VERSION ""

NS_ :

BS_:

BU_: XXX

BO_ 312 MSG_138: 8 XXX
 SG_ SIG_00 : 48|4@1- (1,0) [-1.0|-1.0] "" XXX
 SG_ SIG_01 : 56|4@1- (1,0) [7.0|7.0] "" XXX

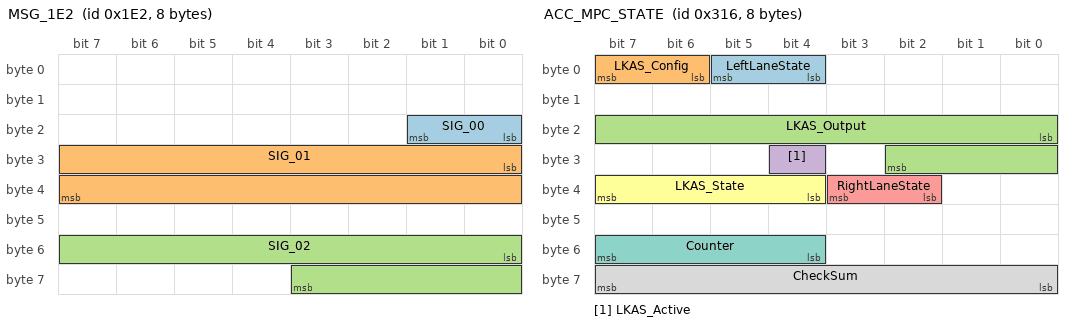
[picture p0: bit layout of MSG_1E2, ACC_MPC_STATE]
BO_ 482 MSG_1E2: 8 XXX
 SG_ SIG_00 : 16|2@1+ (1,0) [2.0|2.0] "" XXX
 SG_ SIG_01 : 24|16@1+ (0.12207217517357137,0) [0.0|8000.0] "" XXX
 SG_ SIG_02 : 48|12@1- (0.06227106227106227,-40) [-166.5970695970696|87.46886446886447] "" XXX

BO_ 790 ACC_MPC_STATE: 8 XXX

 SG_ LeftLaneState : 4|2@1+ (1,0) [0|3] "" XXX
 SG_ LKAS_Config : 6|2@1+ (1,0) [0|3] "" XXX
 SG_ LKAS_Output : 16|11@1- (1,0) [-1024|1023] "" XXX
 SG_ LKAS_Active : 28|1@1+ (1,0) [0|3] "" XXX
 SG_ RightLaneState : 34|2@1+ (1,0) [0|3] "" XXX
 SG_ LKAS_State : 36|4@1+ (1,0) [0|3] "" XXX
 SG_ Counter : 52|4@1+ (1,0) [0|15] "" XXX
 SG_ CheckSum : 56|8@1+ (1,0) [0|15] "" XXX

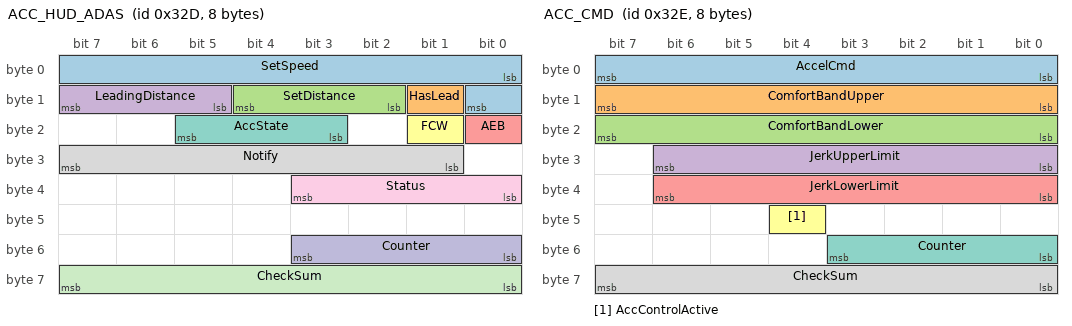
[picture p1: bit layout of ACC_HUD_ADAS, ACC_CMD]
BO_ 813 ACC_HUD_ADAS: 8 XXX

 SG_ SetSpeed : 0|9@1+ (0.5,0) [0|255.5] "" XXX
 SG_ HasLead : 9|1@1+ (1,0) [0|1] "" XXX
 SG_ SetDistance : 10|3@1+ (1,0) [0|7] "" XXX
 SG_ LeadingDistance : 13|3@1+ (1,0) [0|7] "" XXX
 SG_ AEB : 16|1@1+ (1,0) [0|1] "" XXX
 SG_ FCW : 17|1@1+ (1,0) [0|1] "" XXX
 SG_ AccState : 19|3@1+ (1,0) [0|1] "" XXX
 SG_ Notify : 25|7@1+ (1,0) [0|127] "" XXX
 SG_ Status : 32|4@1+ (1,0) [0|15] "" XXX
 SG_ Counter : 48|4@1+ (1,0) [0|15] "" XXX
 SG_ CheckSum : 56|8@1+ (1,0) [0|255] "" XXX

BO_ 814 ACC_CMD: 8 XXX

 SG_ AccelCmd : 0|8@1+ (0.05,-5) [-5|7.75] "" XXX
 SG_ ComfortBandUpper : 8|8@1+ (0.05,-5) [0|1.26] "" XXX
 SG_ ComfortBandLower : 16|8@1+ (0.05,-5) [0|1.26] "" XXX
 SG_ JerkUpperLimit : 24|7@1+ (0.2,0) [0|12.7] "" XXX
 SG_ JerkLowerLimit : 32|7@1+ (0.2,-16) [0|12.7] "" XXX
 SG_ AccControlActive : 44|1@0+ (1,0) [0|1] "" XXX
 SG_ Counter : 48|4@1+ (1,0) [0|15] "" XXX
 SG_ CheckSum : 56|8@1+ (1,0) [0|255] "" XXX

BO_ 815 ACC_AEB: 8 XXX

 SG_ Counter : 48|4@1+ (1,0) [0|15] "" XXX
 SG_ CheckSum : 56|8@1+ (1,0) [0|255] "" XXX

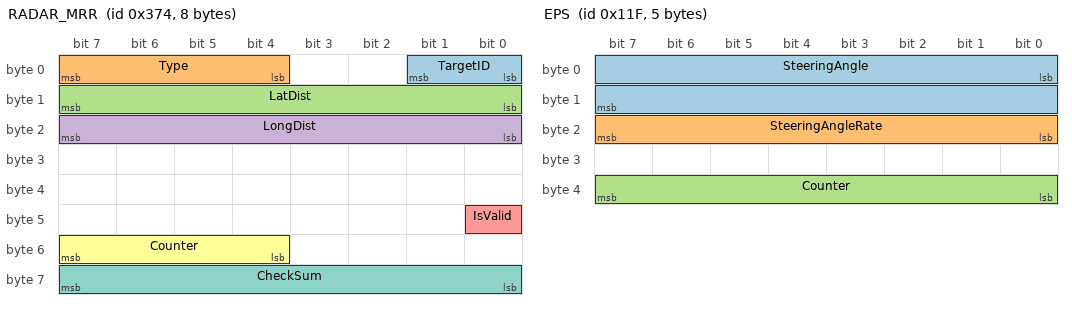
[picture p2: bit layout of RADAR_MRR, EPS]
BO_ 884 RADAR_MRR: 8 XXX

 SG_ TargetID : 1|2@0+ (1,0) [0|3] "" XXX
 SG_ Type : 7|4@0+ (1,0) [0|15] "" XXX
 SG_ LatDist : 15|8@0+ (0.1,-12) [0|255] "" XXX
 SG_ LongDist : 23|8@0+ (1,-100) [0|255] "" XXX
 SG_ IsValid : 40|1@0+ (1,0) [0|3] "" XXX
 SG_ Counter : 52|4@1+ (1,0) [0|15] "" XXX
 SG_ CheckSum : 56|8@1+ (1,0) [0|255] "" XXX

BO_ 287 EPS: 5 XXX

 SG_ SteeringAngle : 0|16@1- (0.1,0) [-450|450] "" XXX
 SG_ SteeringAngleRate : 16|8@1+ (4,0) [0|1020] "" XXX
 SG_ Counter : 32|8@1+ (1,0) [0|255] "" XXX

BO_ 296 MSG_128: 8 XXX
 SG_ SIG_00 : 48|4@1- (1,0) [2.0|2.0] "" XXX
 SG_ SIG_01 : 56|4@1- (1,0) [-4.0|-4.0] "" XXX

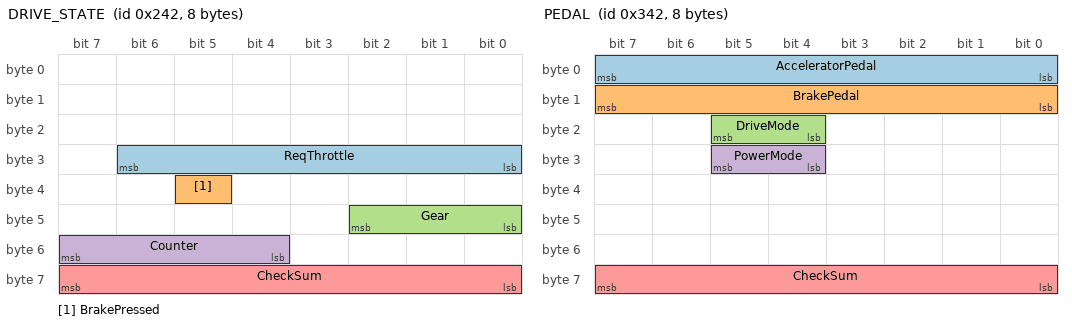
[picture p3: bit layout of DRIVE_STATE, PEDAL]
BO_ 578 DRIVE_STATE: 8 XXX

 SG_ ReqThrottle : 30|7@0+ (1,0) [0|127] "" XXX
 SG_ BrakePressed : 37|1@0+ (1,0) [0|1] "" XXX
 SG_ Gear : 40|3@1+ (1,0) [0|7] "" XXX
 SG_ Counter : 52|4@1+ (1,0) [0|15] "" XXX
 SG_ CheckSum : 56|8@1+ (1,0) [0|255] "" XXX

BO_ 300 MSG_12C: 8 XXX
 SG_ SIG_00 : 48|4@1- (1,0) [0.0|0.0] "" XXX
 SG_ SIG_01 : 56|4@1- (1,0) [-6.0|-6.0] "" XXX

BO_ 834 PEDAL: 8 XXX

 SG_ AcceleratorPedal : 0|8@1+ (1,0) [0|255] "" XXX
 SG_ BrakePedal : 8|8@1+ (1,0) [0|255] "" XXX
 SG_ DriveMode : 20|2@1+ (1,0) [0|255] "" XXX
 SG_ PowerMode : 28|2@1+ (1,0) [0|1] "" XXX
 SG_ CheckSum : 56|8@1+ (1,0) [0|255] "" XXX

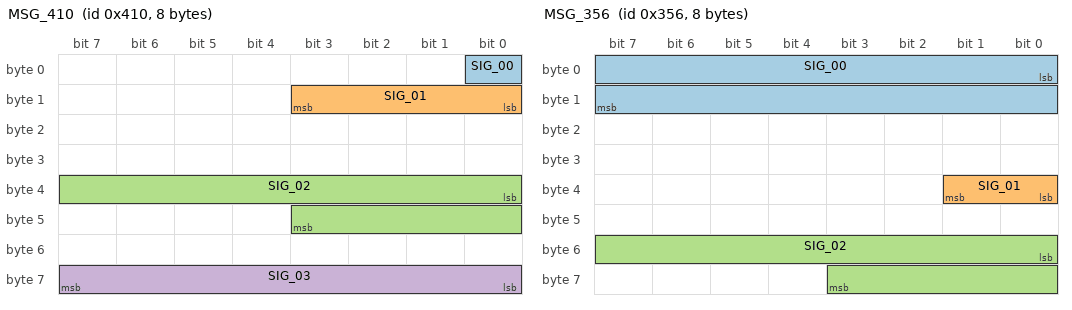
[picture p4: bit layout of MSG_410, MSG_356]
BO_ 1040 MSG_410: 8 XXX
 SG_ SIG_00 : 0|1@1- (1,0) [0.0|0.0] "" XXX
 SG_ SIG_01 : 8|4@1- (1,0) [-5.0|-3.0] "" XXX
 SG_ SIG_02 : 32|12@1- (0.06227106227106227,-40) [-139.57142857142856|-75.8058608058608] "" XXX
 SG_ SIG_03 : 56|8@1+ (1,-40) [-40.0|214.0] "" XXX

BO_ 337 MSG_151: 8 XXX
 SG_ SIG_00 : 0|8@1- (1,-40) [-40.0|-10.0] "" XXX
 SG_ SIG_01 : 48|12@1- (0.06227106227106227,-40) [-166.5970695970696|87.46886446886447] "" XXX

BO_ 854 MSG_356: 8 XXX
 SG_ SIG_00 : 0|16@1- (0.12207217517357137,0) [1464.8661020828565|2256.748302433814] "" XXX
 SG_ SIG_01 : 32|2@1- (1,0) [0.0|0.0] "" XXX
 SG_ SIG_02 : 48|12@1- (0.06227106227106227,-40) [-166.5970695970696|87.46886446886447] "" XXX

BO_ 796 MSG_31C: 64 XXX

BO_ 748 MSG_2EC: 8 XXX
 SG_ SIG_00 : 48|4@1- (1,0) [0.0|0.0] "" XXX
 SG_ SIG_01 : 56|4@1- (1,0) [0.0|0.0] "" XXX

BO_ 604 MSG_25C: 8 XXX

BO_ 803 MSG_323: 8 XXX
 SG_ SIG_00 : 48|4@1- (1,0) [-1.0|-1.0] "" XXX
 SG_ SIG_01 : 56|4@1- (1,0) [-3.0|-3.0] "" XXX

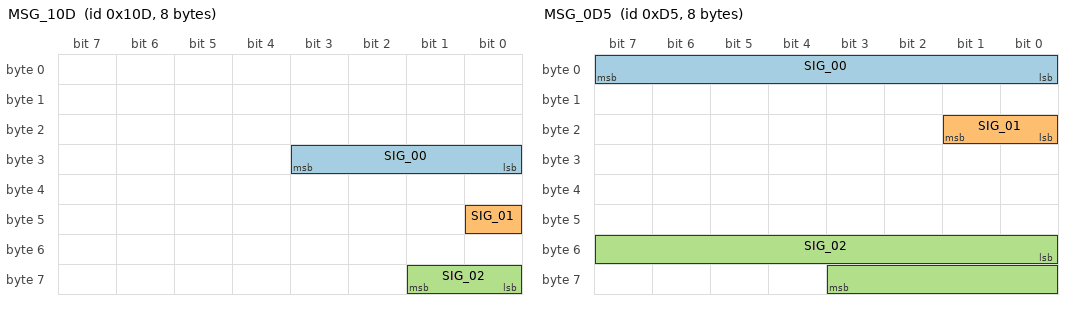
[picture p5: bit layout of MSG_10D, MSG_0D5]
BO_ 269 MSG_10D: 8 XXX
 SG_ SIG_00 : 24|4@1+ (1,0) [3.0|4.0] "" XXX
 SG_ SIG_01 : 40|1@1- (100,0) [-100.0|0.0] "" XXX
 SG_ SIG_02 : 56|2@1+ (1,0) [0.0|0.0] "" XXX

BO_ 213 MSG_0D5: 8 XXX
 SG_ SIG_00 : 0|8@1- (1,-40) [-168.0|87.0] "" XXX
 SG_ SIG_01 : 16|2@1+ (1,0) [1.0|2.0] "" XXX
 SG_ SIG_02 : 48|12@1- (0.06227106227106227,-40) [-166.5970695970696|87.46886446886447] "" XXX

BO_ 289 CARSPEED: 8 XXX

 SG_ CarDisplaySpeed : 0|12@1+ (1,0) [0|255] "" XXX

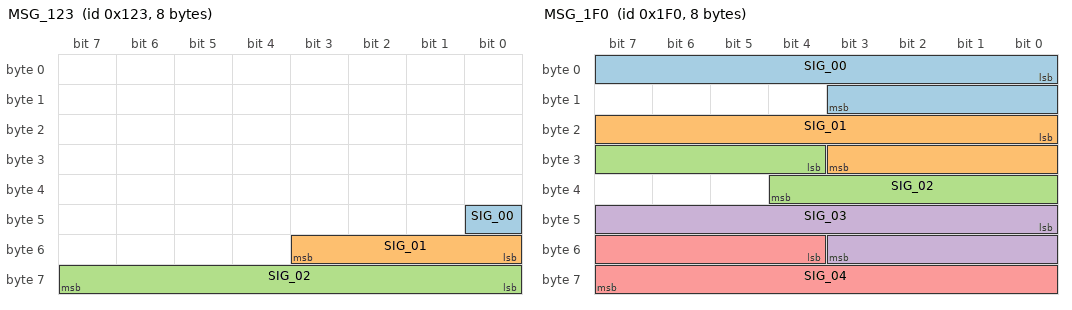
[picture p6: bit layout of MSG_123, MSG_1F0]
BO_ 291 MSG_123: 8 XXX
 SG_ SIG_00 : 40|1@1- (1,0) [0.0|0.0] "" XXX
 SG_ SIG_01 : 48|4@1- (1,0) [-8.0|7.0] "" XXX
 SG_ SIG_02 : 56|8@1- (1,-40) [52.0|75.0] "" XXX

BO_ 1189 MSG_4A5: 8 XXX
 SG_ SIG_00 : 0|4@1- (1,0) [-8.0|7.0] "" XXX
 SG_ SIG_01 : 8|56@1- (1,0) [-3.5167531755953932e+16|2.3057387586478376e+16] "" XXX

BO_ 496 MSG_1F0: 8 XXX
 SG_ SIG_00 : 0|12@1- (0.06227106227106227,-40) [-40.0|-14.904761904761905] "" XXX
 SG_ SIG_01 : 16|12@1- (0.06227106227106227,-40) [-40.0|-14.904761904761905] "" XXX
 SG_ SIG_02 : 28|9@1- (0.49902152641878667,-40) [-167.7495107632094|86.75146771037181] "" XXX
 SG_ SIG_03 : 40|12@1- (0.06227106227106227,-40) [-40.0|-15.02930402930403] "" XXX
 SG_ SIG_04 : 52|12@1- (0.06227106227106227,-40) [-167.53113553113553|87.46886446886447] "" XXX

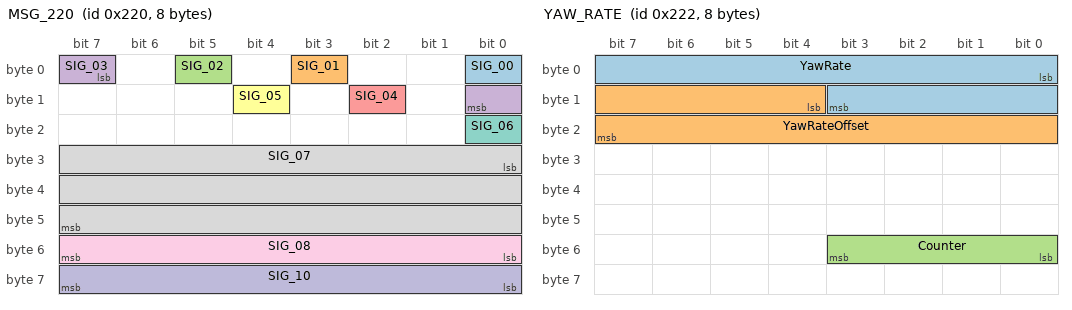
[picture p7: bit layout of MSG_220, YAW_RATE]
BO_ 544 MSG_220: 8 XXX
 SG_ SIG_00 : 0|1@1- (1,0) [-1.0|-1.0] "" XXX
 SG_ SIG_01 : 3|1@1- (100,0) [-100.0|0.0] "" XXX
 SG_ SIG_02 : 5|1@1- (100,0) [-100.0|0.0] "" XXX
 SG_ SIG_03 : 7|2@1- (1,0) [-1.0|1.0] "" XXX
 SG_ SIG_04 : 10|1@1- (100,0) [-100.0|0.0] "" XXX
 SG_ SIG_05 : 12|1@1- (100,0) [-100.0|0.0] "" XXX
 SG_ SIG_06 : 16|1@1- (1,0) [0.0|0.0] "" XXX
 SG_ SIG_07 : 24|24@1+ (1,0) [106.0|3505320.0] "" XXX
 SG_ SIG_08 : 48|8@1+ (1,-40) [-8.0|83.0] "" XXX
 SG_ SIG_10 : 56|8@1- (1,-40) [-168.0|87.0] "" XXX

BO_ 546 YAW_RATE: 8 XXX

 SG_ YawRate : 0|12@1+ (0.002133,-2.094) [-2.0|2.0] "rad/s" XXX
 SG_ YawRateOffset : 12|12@1+ (0.002133,-0.13) [-0.1|0.1] "rad/s" XXX
 SG_ Counter : 48|4@1+ (1,0) [0|15] "" XXX

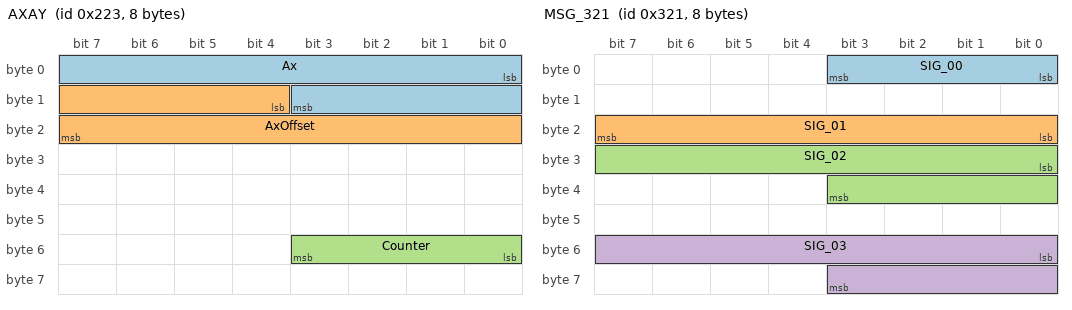
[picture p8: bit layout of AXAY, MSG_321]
BO_ 547 AXAY: 8 XXX

 SG_ Ax : 0|12@1+ (0.027167,-21.593) [-10.0|10.0] "m/s^2" XXX
 SG_ AxOffset : 12|12@1+ (0.027127,-21.593) [-1.0|1.0] "m/s^2" XXX
 SG_ Counter : 48|4@1+ (1,0) [0|15] "" XXX

BO_ 801 MSG_321: 8 XXX
 SG_ SIG_00 : 0|4@1+ (1,0) [0.0|4.0] "" XXX
 SG_ SIG_01 : 16|8@1- (1,-40) [-24.0|61.0] "" XXX
 SG_ SIG_02 : 24|12@1- (0.06227106227106227,-40) [-160.55677655677655|78.56410256410257] "" XXX
 SG_ SIG_03 : 48|12@1- (0.06227106227106227,-40) [-166.97069597069597|87.0952380952381] "" XXX

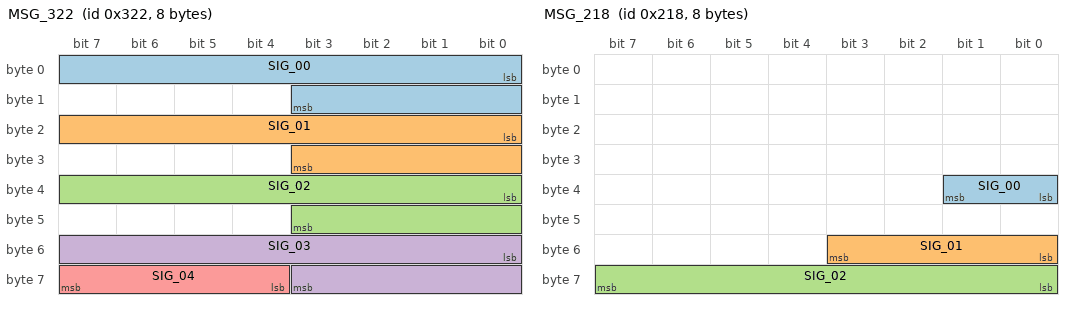
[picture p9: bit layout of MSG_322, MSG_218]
BO_ 802 MSG_322: 8 XXX
 SG_ SIG_00 : 0|12@1+ (0.06227106227106227,-40) [23.765567765567766|87.28205128205128] "" XXX
 SG_ SIG_01 : 16|12@1+ (0.06227106227106227,-40) [-40.0|23.578754578754577] "" XXX
 SG_ SIG_02 : 32|12@1- (0.06227106227106227,-40) [-40.0|45.12454212454213] "" XXX
 SG_ SIG_03 : 48|12@1- (0.06227106227106227,-40) [-40.0|46.05860805860806] "" XXX
 SG_ SIG_04 : 60|4@1- (1,0) [-8.0|7.0] "" XXX

BO_ 536 MSG_218: 8 XXX
 SG_ SIG_00 : 32|2@1- (1,0) [0.0|0.0] "" XXX
 SG_ SIG_01 : 48|4@1- (1,0) [-8.0|7.0] "" XXX
 SG_ SIG_02 : 56|8@1+ (1,-40) [-38.0|165.0] "" XXX

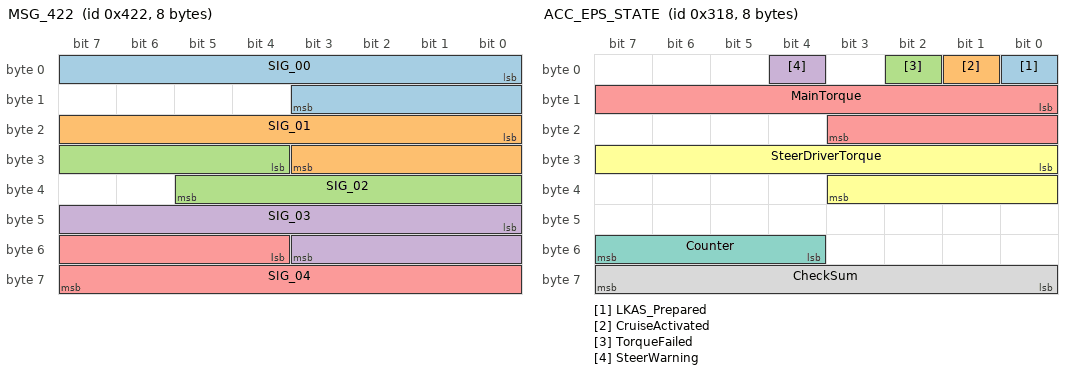
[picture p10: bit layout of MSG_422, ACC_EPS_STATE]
BO_ 1058 MSG_422: 8 XXX
 SG_ SIG_00 : 0|12@1+ (0.06227106227106227,-40) [151.2967032967033|214.8131868131868] "" XXX
 SG_ SIG_01 : 16|12@1+ (0.06227106227106227,-40) [151.2967032967033|214.87545787545787] "" XXX
 SG_ SIG_02 : 28|10@1+ (0.09775171065493646,0) [0.0|99.80449657869012] "" XXX
 SG_ SIG_03 : 40|12@1+ (0.06227106227106227,-40) [151.2967032967033|214.93772893772893] "" XXX
 SG_ SIG_04 : 52|12@1- (0.06227106227106227,-40) [-167.34432234432234|87.4065934065934] "" XXX

BO_ 660 BELT: 8 XXX

 SG_ SeatBelt : 16|2@1+ (1,0) [0|3] "" XXX

BO_ 508 MSG_1FC: 8 XXX
 SG_ SIG_00 : 48|4@1- (1,0) [-1.0|-1.0] "" XXX
 SG_ SIG_01 : 56|4@1- (1,0) [6.0|6.0] "" XXX

BO_ 792 ACC_EPS_STATE: 8 XXX

 SG_ LKAS_Prepared : 0|1@1+ (1,0) [0|1] "" XXX
 SG_ CruiseActivated : 1|1@1+ (1,0) [0|1] "" XXX
 SG_ TorqueFailed : 2|1@1+ (1,0) [0|1] "" XXX
 SG_ SteerWarning : 4|1@1+ (1,0) [0|1] "" XXX
 SG_ MainTorque : 8|12@1- (1,0) [-2048|2047] "" XXX
 SG_ SteerDriverTorque : 24|12@1- (1,0) [-2048|2047] "" XXX
 SG_ Counter : 52|4@1+ (1,0) [0|15] "" XXX
 SG_ CheckSum : 56|8@1+ (1,0) [0|255] "" XXX

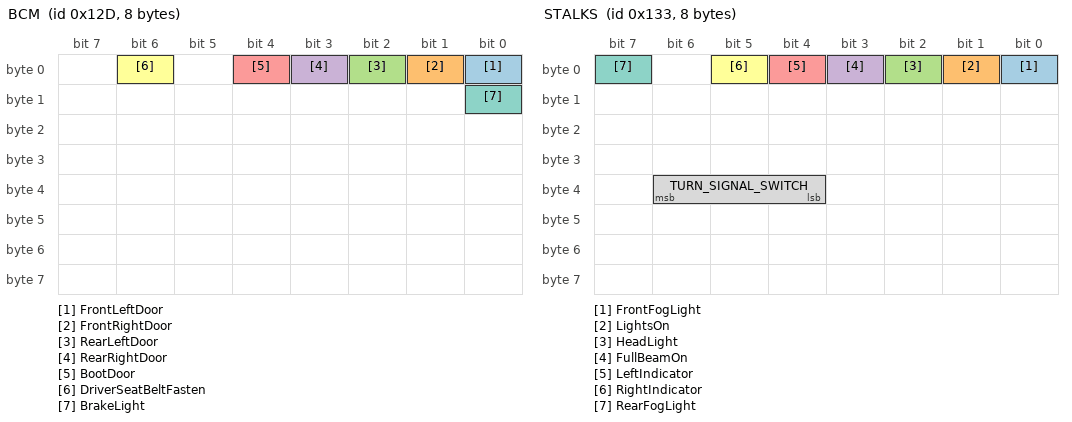
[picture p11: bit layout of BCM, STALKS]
BO_ 301 BCM: 8 XXX

 SG_ FrontLeftDoor : 0|1@0+ (1,0) [0|1] "" XXX
 SG_ FrontRightDoor : 1|1@0+ (1,0) [0|1] "" XXX
 SG_ RearLeftDoor : 2|1@0+ (1,0) [0|1] "" XXX
 SG_ RearRightDoor : 3|1@0+ (1,0) [0|1] "" XXX
 SG_ BootDoor : 4|1@0+ (1,0) [0|1] "" XXX
 SG_ DriverSeatBeltFasten : 6|1@0+ (1,0) [0|1] "" XXX
 SG_ BrakeLight : 8|1@0+ (1,0) [0|1] "" XXX

BO_ 798 MSG_31E: 8 XXX

BO_ 575 MSG_23F: 8 XXX
 SG_ SIG_00 : 48|4@1- (1,0) [0.0|0.0] "" XXX
 SG_ SIG_01 : 56|4@1- (1,0) [-1.0|-1.0] "" XXX

BO_ 1028 MSG_404: 8 XXX
 SG_ SIG_00 : 56|4@1- (1,0) [-3.0|-3.0] "" XXX

BO_ 307 STALKS: 8 XXX

 SG_ FrontFogLight : 0|1@0+ (1,0) [0|1] "" XXX
 SG_ LightsOn : 1|1@1+ (1,0) [0|1] "" XXX
 SG_ HeadLight : 2|1@1+ (1,0) [0|1] "" XXX
 SG_ FullBeamOn : 3|1@1+ (1,0) [0|1] "" XXX
 SG_ LeftIndicator : 4|1@0+ (1,0) [0|1] "" XXX
 SG_ RightIndicator : 5|1@0+ (1,0) [0|1] "" XXX
 SG_ RearFogLight : 7|1@0+ (1,0) [0|1] "" XXX
 SG_ TURN_SIGNAL_SWITCH : 36|3@1+ (1,0) [0|7] "" XXX

BO_ 985 MSG_3D9: 8 XXX
 SG_ SIG_00 : 0|4@1- (1,0) [1.0|7.0] "" XXX
 SG_ SIG_01 : 8|56@1- (1,0) [-3.6008833800122276e+16|3.5908022749450332e+16] "" XXX

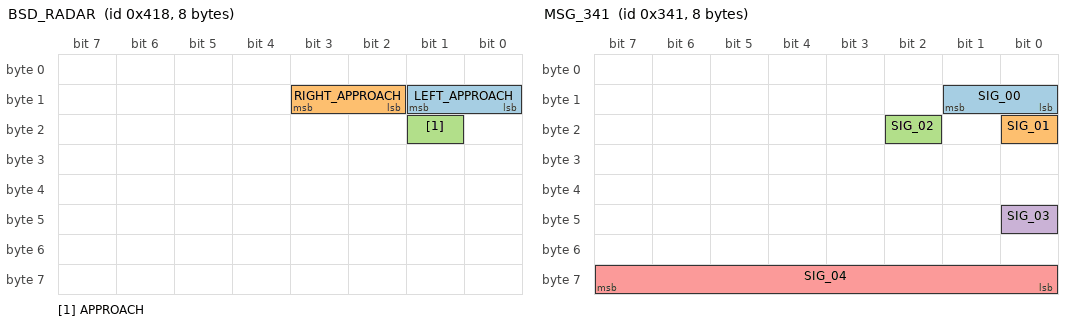
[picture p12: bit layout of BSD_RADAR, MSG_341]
BO_ 1048 BSD_RADAR: 8 XXX

 SG_ LEFT_APPROACH : 9|2@0+ (1,0) [0|1] "" XXX
 SG_ RIGHT_APPROACH : 11|2@0+ (1,0) [0|1] "" XXX
 SG_ APPROACH : 17|1@0+ (1,0) [0|1] "" XXX

BO_ 860 MSG_35C: 8 XXX
 SG_ SIG_00 : 48|4@1- (1,0) [-4.0|-4.0] "" XXX
 SG_ SIG_01 : 56|4@1- (1,0) [-7.0|-7.0] "" XXX

BO_ 797 MSG_31D: 8 XXX

BO_ 833 MSG_341: 8 XXX
 SG_ SIG_00 : 8|2@1- (1,0) [1.0|1.0] "" XXX
 SG_ SIG_01 : 16|1@1- (100,0) [-100.0|0.0] "" XXX
 SG_ SIG_02 : 18|1@1+ (100,0) [0.0|100.0] "" XXX
 SG_ SIG_03 : 40|1@1- (100,0) [-100.0|0.0] "" XXX
 SG_ SIG_04 : 56|8@1- (1,-40) [-114.0|-94.0] "" XXX

BO_ 836 MSG_344: 8 XXX

BO_ 668 MSG_29C: 8 XXX
 SG_ SIG_00 : 48|4@1- (1,0) [-1.0|-1.0] "" XXX
 SG_ SIG_01 : 56|4@1- (1,0) [4.0|4.0] "" XXX

BO_ 692 MSG_2B4: 8 XXX
 SG_ SIG_00 : 0|2@1+ (1,0) [1.0|2.0] "" XXX

BO_ 714 MSG_2CA: 8 XXX
 SG_ SIG_00 : 48|4@1- (1,0) [-1.0|-1.0] "" XXX
 SG_ SIG_01 : 56|4@1- (1,0) [-5.0|-5.0] "" XXX

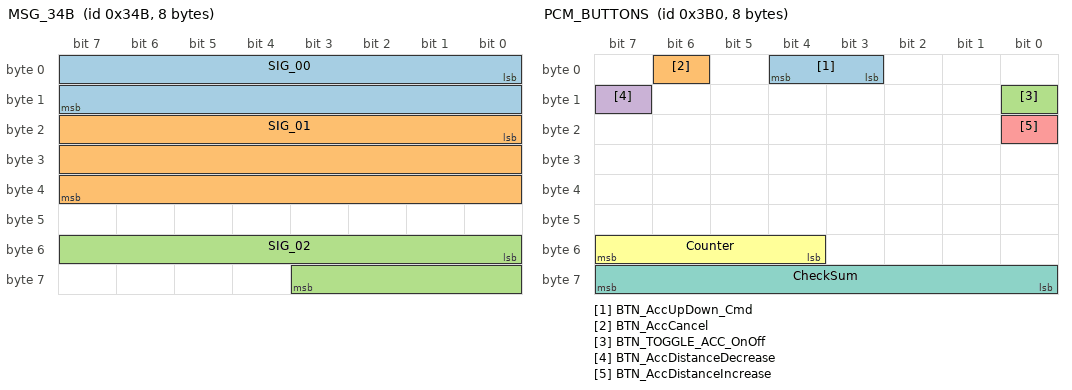
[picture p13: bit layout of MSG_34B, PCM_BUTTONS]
BO_ 843 MSG_34B: 8 XXX
 SG_ SIG_00 : 0|16@1+ (0.12207217517357137,0) [4000.0610360875867|5739.589532310979] "" XXX
 SG_ SIG_01 : 16|24@1- (1,0) [-8387126.0|8386560.0] "" XXX
 SG_ SIG_02 : 48|12@1- (0.06227106227106227,-40) [-166.5970695970696|87.46886446886447] "" XXX

BO_ 944 PCM_BUTTONS: 8 XXX

 SG_ BTN_AccUpDown_Cmd : 4|2@0+ (1,0) [0|3] "" XXX
 SG_ BTN_AccCancel : 6|1@0+ (1,0) [0|1] "" XXX
 SG_ BTN_TOGGLE_ACC_OnOff : 8|1@0+ (1,0) [0|1] "" XXX
 SG_ BTN_AccDistanceDecrease : 15|1@0+ (1,0) [0|1] "" XXX
 SG_ BTN_AccDistanceIncrease : 16|1@0+ (1,0) [0|1] "" XXX
 SG_ Counter : 52|4@1+ (1,0) [0|15] "" XXX
 SG_ CheckSum : 56|8@1+ (1,0) [0|255] "" XXX

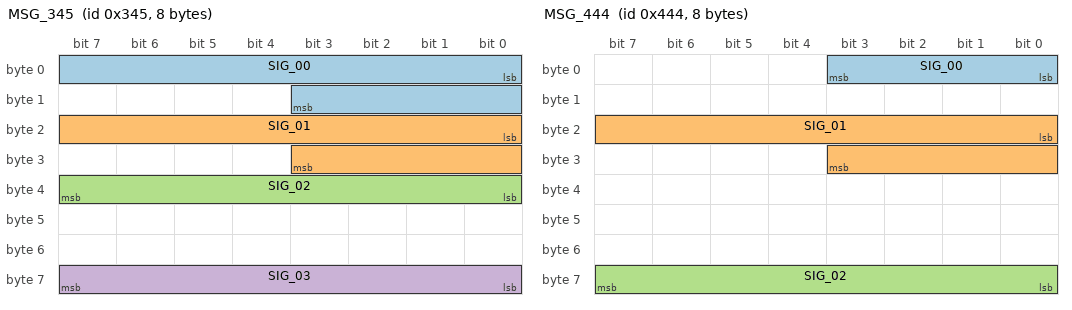
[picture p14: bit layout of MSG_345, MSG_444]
BO_ 837 MSG_345: 8 XXX
 SG_ SIG_00 : 0|12@1- (0.06227106227106227,-40) [-9.487179487179485|-5.81318681318681] "" XXX
 SG_ SIG_01 : 16|12@1- (0.06227106227106227,-40) [2.344322344322343|33.66666666666667] "" XXX
 SG_ SIG_02 : 32|8@1- (1,-40) [-166.0|87.0] "" XXX
 SG_ SIG_03 : 56|8@1- (1,-40) [-163.0|86.0] "" XXX

BO_ 1092 MSG_444: 8 XXX
 SG_ SIG_00 : 0|4@1+ (1,0) [2.0|9.0] "" XXX
 SG_ SIG_01 : 16|12@1+ (0.06227106227106227,-40) [-2.6996336996337007|44.31501831501832] "" XXX
 SG_ SIG_02 : 56|8@1+ (1,-40) [-40.0|215.0] "" XXX

BO_ 1107 MSG_453: 8 XXX

BO_ 576 MSG_240: 8 XXX
 SG_ SIG_00 : 48|4@1- (1,0) [0.0|0.0] "" XXX
 SG_ SIG_01 : 56|4@1- (1,0) [-2.0|-2.0] "" XXX

BO_ 1214 MSG_4BE: 8 XXX

BO_ 1193 MSG_4A9: 8 XXX

BO_ 1297 MSG_511: 8 XXX

BO_ 1365 MSG_555: 8 XXX

BO_ 1366 MSG_556: 8 XXX

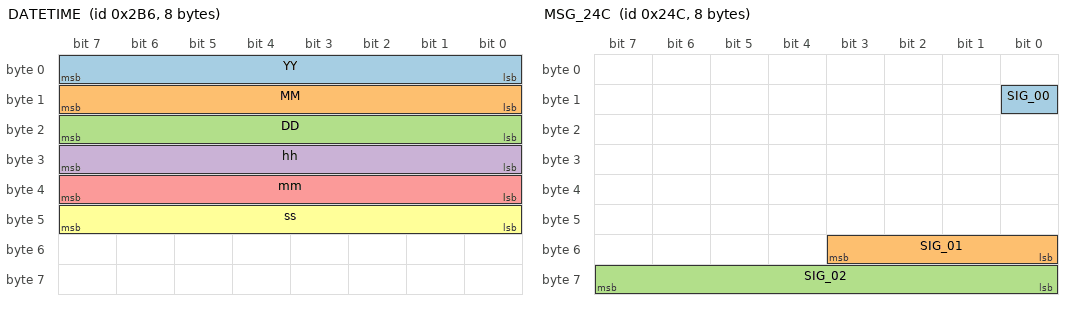
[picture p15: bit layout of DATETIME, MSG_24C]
BO_ 694 DATETIME: 8 XXX

 SG_ YY : 7|8@0+ (1,0) [0|255] "" XXX
 SG_ MM : 15|8@0+ (1,0) [0|255] "" XXX
 SG_ DD : 23|8@0+ (1,0) [0|255] "" XXX
 SG_ hh : 31|8@0+ (1,0) [0|255] "" XXX
 SG_ mm : 39|8@0+ (1,0) [0|255] "" XXX
 SG_ ss : 47|8@0+ (1,0) [0|255] "" XXX

BO_ 588 MSG_24C: 8 XXX
 SG_ SIG_00 : 8|1@1+ (1,0) [1.0|1.0] "" XXX
 SG_ SIG_01 : 48|4@1- (1,0) [-1.0|-1.0] "" XXX
 SG_ SIG_02 : 56|8@1- (1,-40) [-161.0|87.0] "" XXX

BO_ 1093 MSG_445: 8 XXX
 SG_ SIG_00 : 40|12@1- (0.06227106227106227,-40) [-71.94505494505495|-65.84249084249085] "" XXX
 SG_ SIG_01 : 56|8@1- (1,-40) [-112.0|-13.0] "" XXX

BO_ 941 MSG_3AD: 8 XXX

BO_ 1246 MSG_4DE: 8 XXX

BO_ 1029 MSG_405: 8 XXX

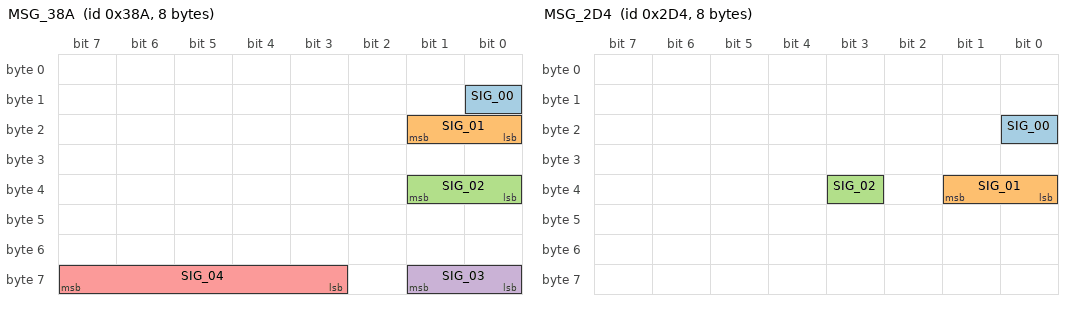
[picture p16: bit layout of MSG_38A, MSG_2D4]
BO_ 906 MSG_38A: 8 XXX
 SG_ SIG_00 : 8|1@1- (1,0) [0.0|0.0] "" XXX
 SG_ SIG_01 : 16|2@1- (1,0) [-2.0|1.0] "" XXX
 SG_ SIG_02 : 32|2@1+ (1,0) [1.0|1.0] "" XXX
 SG_ SIG_03 : 56|2@1+ (1,0) [1.0|2.0] "" XXX
 SG_ SIG_04 : 59|5@1+ (1,0) [0.0|31.0] "" XXX

BO_ 1319 MSG_527: 8 XXX

BO_ 758 MSG_2F6: 8 XXX

BO_ 1074 MSG_432: 8 XXX

BO_ 904 MSG_388: 8 XXX

BO_ 1166 MSG_48E: 8 XXX

BO_ 1203 MSG_4B3: 64 XXX

BO_ 1322 MSG_52A: 8 XXX

BO_ 965 MSG_3C5: 8 XXX

BO_ 1178 MSG_49A: 8 XXX

BO_ 1141 MSG_475: 8 XXX

BO_ 1031 MSG_407: 8 XXX

BO_ 1033 MSG_409: 8 XXX
 SG_ SIG_00 : 0|4@1+ (1,0) [1.0|9.0] "" XXX
 SG_ SIG_01 : 8|51@1+ (1,0) [0.0|2251799813684992.0] "" XXX

BO_ 951 MSG_3B7: 8 XXX
 SG_ SIG_00 : 0|8@1- (1,-40) [-40.0|-13.0] "" XXX
 SG_ SIG_01 : 48|12@1- (0.06227106227106227,-40) [-121.6996336996337|86.53479853479854] "" XXX

BO_ 724 MSG_2D4: 8 XXX
 SG_ SIG_00 : 16|1@1- (100,0) [-100.0|0.0] "" XXX
 SG_ SIG_01 : 32|2@1- (1,0) [-2.0|1.0] "" XXX
 SG_ SIG_02 : 35|1@1- (100,0) [-100.0|0.0] "" XXX

BO_ 1204 MSG_4B4: 64 XXX

BO_ 1023 MSG_3FF: 8 XXX
 SG_ SIG_00 : 40|2@1+ (1,0) [3.0|3.0] "" XXX

BO_ 1226 MSG_4CA: 16 XXX
 SG_ SIG_00 : 16|4@1- (1,0) [0.0|4.0] "" XXX
 SG_ SIG_01 : 32|2@1- (1,0) [0.0|0.0] "" XXX

BO_ 140 MSG_08C: 8 XXX
 SG_ SIG_00 : 8|4@1- (1,0) [0.0|0.0] "" XXX
 SG_ SIG_01 : 56|4@1- (1,0) [0.0|0.0] "" XXX

BO_ 940 MSG_3AC: 8 XXX
 SG_ SIG_00 : 16|2@1+ (1,0) [1.0|2.0] "" XXX
 SG_ SIG_01 : 32|2@1- (1,0) [-2.0|-2.0] "" XXX

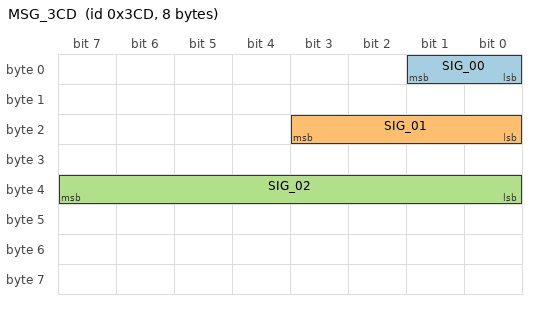
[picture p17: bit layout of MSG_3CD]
BO_ 973 MSG_3CD: 8 XXX
 SG_ SIG_00 : 0|2@1- (1,0) [-2.0|1.0] "" XXX
 SG_ SIG_01 : 16|4@1+ (1,0) [2.0|10.0] "" XXX
 SG_ SIG_02 : 32|8@1+ (1,-40) [26.0|76.0] "" XXX

BO_ 948 MSG_3B4: 8 XXX
 SG_ SIG_00 : 0|4@1- (1,0) [-5.0|-4.0] "" XXX
 SG_ SIG_01 : 8|2@1+ (1,0) [1.0|2.0] "" XXX

VAL_ 578 Gear 4 "D" 2 "R" 3 "N" 1 "P" ;
VAL_ 790 LeftLaneState 0 "GRAY" 1 "GREEN" 2 "YELLOW" 3 "RED" ;
VAL_ 790 RightLaneState 0 "GRAY" 1 "GREEN" 2 "YELLOW" 3 "RED" ;
VAL_ 813 SetDistance 4 "4BAR" 3 "3BAR" 2 "2BAR" 1 "1BAR" ;
VAL_ 813 AccState 0 "OFF" 2 "ACC_ON" 3 "ACC_ACTIVE" 5 "FORCE_ACCEL" 7 "ERROR" ;
VAL_ 834 DriveMode 2 "SPORT" 1 "ECO" 0 "SNOW" ;
VAL_ 834 PowerMode 3 "HEV" 2 "FORCE_EV" 1 "EV" ;
VAL_ 944 BTN_AccUpDown_Cmd 0 "NOTPRESSED" 1 "DOWN_SETSPEED" 3 "UP_RESETSPEED" ;
